# PIC64GX register map
Vendor: Microchip; Series: PIC64GX; File version: 0.1
Minimal PIC64GX device description for MMUART2_LO-only hello world bring-up.
Registers are 32-bit, read-write, reset 0x0 unless marked. A register's access mark holds for its fields unless they carry their own. Offsets are from the block's base; lines under a group give offsets from that group; [hi:lo] are bit positions; {n}, {i} and the like mark numbered series; 'fields as' and 'values as' point back to an identical list; <NAME> marks a mode.

## Memory map
0x20102000 UART2 size 0x18 — Minimal MMUART2_LO view for a standalone UART hello world payload.

## UART2 — Minimal MMUART2_LO view for a standalone UART hello world payload.
Base 0x20102000
0x00 THR wo — Transmit Holding Register
  [7:0] DATA — Byte to transmit
0x00 DLR (alternate view of THR) — Divisor Latch Register (LSB) when LCR.DLAB is set
  [7:0] DIVISOR_LSB — Baud divisor least-significant byte
0x04 DMR — Divisor Latch Register (MSB) when LCR.DLAB is set
  [7:0] DIVISOR_MSB — Baud divisor most-significant byte
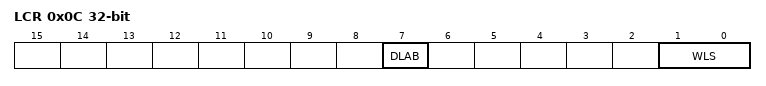
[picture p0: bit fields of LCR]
0x0C LCR — Line Control Register
  [7] DLAB — Divisor latch access bit
  [1:0] WLS — Word length select
0x14 LSR ro — Line Status Register
  [5] THRE — Transmit holding register empty

## Licence text in the file
Derived from the public Microchip PIC64GX register map documentation for MMUART.
